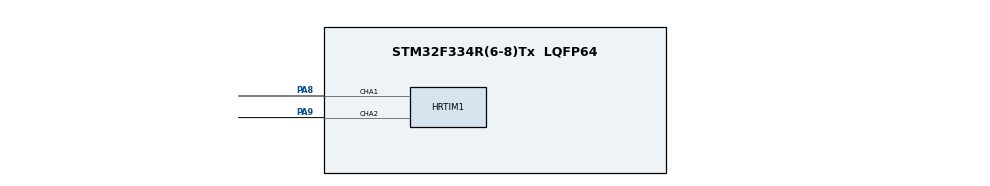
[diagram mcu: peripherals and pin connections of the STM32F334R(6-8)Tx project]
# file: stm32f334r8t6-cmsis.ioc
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Mcu.Family=STM32F3
Mcu.Name=STM32F334R(6-8)Tx
Mcu.Package=LQFP64
NVIC.PriorityGroup=NVIC_PRIORITYGROUP_4
PA13.Mode=Serial_Wire
PA13.Signal=SYS_JTMS-SWDIO
PA14.Mode=Serial_Wire
PA14.Signal=SYS_JTCK-SWCLK
PA8.Mode=Output_TA1TA2
PA8.Signal=HRTIM1_CHA1
PA9.Mode=Output_TA1TA2
PA9.Signal=HRTIM1_CHA2
PC14\ /\ OSC32_IN.Mode=LSE-External-Oscillator
PC14\ /\ OSC32_IN.Signal=RCC_OSC32_IN
PC15\ /\ OSC32_OUT.Mode=LSE-External-Oscillator
PC15\ /\ OSC32_OUT.Signal=RCC_OSC32_OUT
PF0\ /\ OSC_IN.Mode=HSE-External-Oscillator
PF0\ /\ OSC_IN.Signal=RCC_OSC_IN
PF1\ /\ OSC_OUT.Mode=HSE-External-Oscillator
PF1\ /\ OSC_OUT.Signal=RCC_OSC_OUT
ProjectManager.HeapSize=0x200
ProjectManager.StackSize=0x400
ProjectManager.TargetToolchain=STM32CubeIDE
RCC.AHBFreq_Value=8000000
RCC.APB1Freq_Value=8000000
RCC.APB2Freq_Value=8000000
RCC.CortexFreq_Value=8000000
RCC.HSE_VALUE=8000000
RCC.HSI_VALUE=8000000
RCC.SYSCLKFreq_VALUE=8000000
VP_HRTIM1_VS_hrtimMasterTimerNoOutput.Mode=MasterTimer
board=custom

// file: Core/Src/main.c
/* USER CODE BEGIN Header */
/**
  ******************************************************************************
  * @file           : main.c
  * @brief          : Main program body
  ******************************************************************************
  * @attention
  *
  * Copyright (c) 2023 STMicroelectronics.
  * All rights reserved.
  *
  * This software is licensed under terms that can be found in the LICENSE file
  * in the root directory of this software component.
  * If no LICENSE file comes with this software, it is provided AS-IS.
  *
  ******************************************************************************
  */
/* USER CODE END Header */
#include "main.h"
#include "SysTick.h"
#include "led.h"
#include "init_hrtim.h"
/* USER CODE BEGIN Includes */
extern volatile uint32_t led_delay;
extern uint16_t repetition_rate;

uint16_t curr_duty;
uint32_t curr_freq;
uint8_t  ticks;

/* USER CODE END Includes */

void SystemClock_Config(void);
/* USER CODE BEGIN PFP */
void PllOn_F334(void);
void enable_led1();
void initHRTIM(void);
void startHRTIM(void);
void freq_up(uint16_t delta_period);
void freq_down(uint16_t delta_period);
void duty_down(uint16_t duty);
void set_duty(uint16_t duty);
void set_freq(uint32_t freq);
void init_user_button(void);

/* USER CODE END PFP */

int main(void)
{
  /* USER CODE BEGIN 1 */
	//  PllOn_F334();
	SystemUp_F334();
	init_SysTick();
	enable_led1();
	initHRTIM();
	init_user_button();

  /* USER CODE END 1 */

  /* MCU Configuration--------------------------------------------------------*/

  /* Reset of all peripherals, Initializes the Flash interface and the Systick. */

  /* Configure the system clock */
//  SystemClock_Config();

  /* Initialize all configured peripherals */
//  MX_GPIO_Init();
//  MX_HRTIM1_Init();

  /* Infinite loop */
  /* USER CODE BEGIN WHILE */
  ticks_delay=0;
  ticks=0;

  startHRTIM();
  while (1)
  {
	if(ticks_delay>=led_delay){
			LED1_TOGGLE;
			ticks_delay=0;
//			ticks++;

			curr_duty=(CHANNEL_DUTY!=CHANNEL_PERIOD)?CHANNEL_PERIOD:CHANNEL_PERIOD/2;
			set_duty(curr_duty);
	}
//	if(ticks_delay>=led_delay && ticks>3){
//		ticks_delay=0;
//		ticks++;
//
//		curr_freq=(FHRCK/HRTIM_FULL_PERIOD==75000)?100000:75000;
//		set_freq(curr_freq);
//		if(ticks>7)
//			ticks=0;
//    }
    /* USER CODE END WHILE */
  }
}

void Error_Handler(void)
{
  __disable_irq();
  while (1)
  {
  }
}
